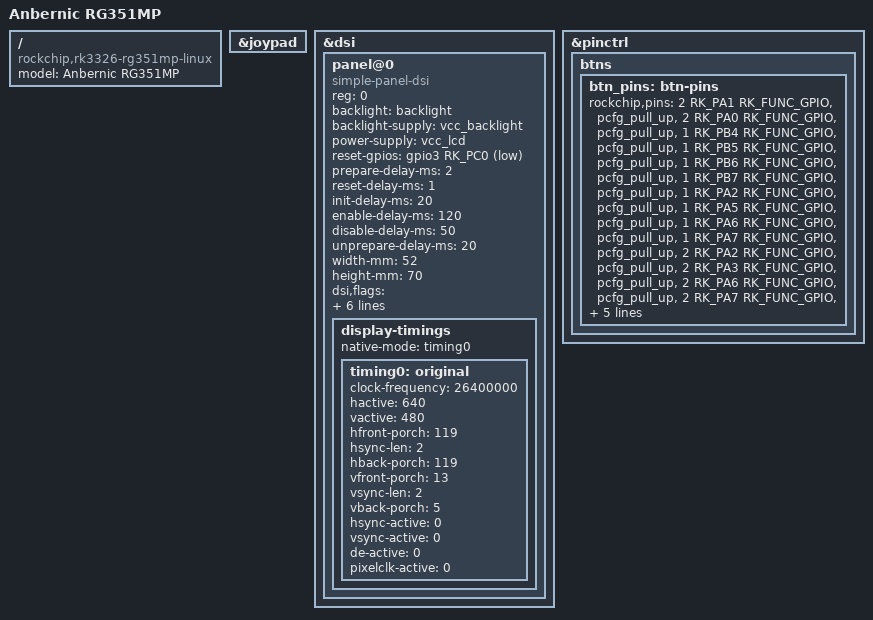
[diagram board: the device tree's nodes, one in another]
// SPDX-License-Identifier: (GPL-2.0+ OR MIT)
/*
* Copyright (c) 2026 kk&lcdyk
*
* Anbernic RG351MP
*
*/

/dts-v1/;
#include "rk3326-r36s-panel0-linux.dts"

/ {
	model = "Anbernic RG351MP";
	compatible = "rockchip,rk3326-rg351mp-linux", "rockchip,rk3326";
};

&joypad {
    /delete-node/ sw13;
};

&dsi {
	status = "okay";
	
	panel@0 {
		compatible = "simple-panel-dsi";
		reg = <0>;
		/* pwm1 backlight */
		backlight = <&backlight>;
		/* RK817 LDO7 */
		backlight-supply = <&vcc_backlight>;
		/* RK817 LDO8 */
		power-supply = <&vcc_lcd>;
		/* Rev 0.2 LCD reset gpio GPIO3.C0 */
		reset-gpios = <&gpio3 RK_PC0 GPIO_ACTIVE_LOW>;
		prepare-delay-ms = <2>;
		reset-delay-ms = <1>;
		init-delay-ms = <20>;
		enable-delay-ms = <120>;
		disable-delay-ms = <50>;
		unprepare-delay-ms = <20>;
		width-mm = <52>;
		height-mm = <70>;
		dsi,flags  = <(MIPI_DSI_MODE_VIDEO |
		MIPI_DSI_MODE_VIDEO_BURST |
		MIPI_DSI_MODE_LPM |
		MIPI_DSI_MODE_EOT_PACKET)>;
		dsi,format = <MIPI_DSI_FMT_RGB888>;
		dsi,lanes = <4>;
		panel-init-sequence = [ 15 00 02 FF 30 15 00 02 FF 52 15 00 02 FF 01 15 00 02 E3 00 15 00 02 40 0A 15 00 02 03 40 15 00 02 04 00 15 00 02 05 03 15 00 02 24 12 15 00 02 25 1E 15 00 02 26 28 15 00 02 27 52 15 00 02 28 57 15 00 02 29 01 15 00 02 2A DF 15 00 02 38 9C 15 00 02 39 A7 15 00 02 3A 53 15 00 02 44 00 15 00 02 49 3C 15 00 02 59 FE 15 00 02 5C 00 15 00 02 91 77 15 00 02 92 77 15 00 02 A0 55 15 00 02 A1 50 15 00 02 A4 9C 15 00 02 A7 02 15 00 02 A8 01 15 00 02 A9 01 15 00 02 AA FC 15 00 02 AB 28 15 00 02 AC 06 15 00 02 AD 06 15 00 02 AE 06 15 00 02 AF 03 15 00 02 B0 08 15 00 02 B1 26 15 00 02 B2 28 15 00 02 B3 28 15 00 02 B4 33 15 00 02 B5 08 15 00 02 B6 26 15 00 02 B7 08 15 00 02 B8 26 15 00 02 FF 30 15 00 02 FF 52 15 00 02 FF 02 15 00 02 B0 0B 15 00 02 B1 16 15 00 02 B2 17 15 00 02 B3 2C 15 00 02 B4 32 15 00 02 B5 3B 15 00 02 B6 29 15 00 02 B7 40 15 00 02 B8 0D 15 00 02 B9 05 15 00 02 BA 12 15 00 02 BB 10 15 00 02 BC 12 15 00 02 BD 15 15 00 02 BE 19 15 00 02 BF 0E 15 00 02 C0 16 15 00 02 C1 0A 15 00 02 D0 0C 15 00 02 D1 17 15 00 02 D2 14 15 00 02 D3 2E 15 00 02 D4 32 15 00 02 D5 3C 15 00 02 D6 22 15 00 02 D7 3D 15 00 02 D8 0D 15 00 02 D9 07 15 00 02 DA 13 15 00 02 DB 13 15 00 02 DC 11 15 00 02 DD 15 15 00 02 DE 19 15 00 02 DF 10 15 00 02 E0 17 15 00 02 E1 0A 15 00 02 FF 30 15 00 02 FF 52 15 00 02 FF 03 15 00 02 00 2A 15 00 02 01 2A 15 00 02 02 2A 15 00 02 03 2A 15 00 02 04 61 15 00 02 05 80 15 00 02 06 C7 15 00 02 07 01 15 00 02 08 82 15 00 02 09 83 15 00 02 30 2A 15 00 02 31 2A 15 00 02 32 2A 15 00 02 33 2A 15 00 02 34 61 15 00 02 35 C5 15 00 02 36 80 15 00 02 37 23 15 00 02 40 82 15 00 02 41 83 15 00 02 42 80 15 00 02 43 81 15 00 02 44 11 15 00 02 45 E6 15 00 02 46 E5 15 00 02 47 11 15 00 02 48 E8 15 00 02 49 E7 15 00 02 50 02 15 00 02 51 01 15 00 02 52 04 15 00 02 53 03 15 00 02 54 11 15 00 02 55 EA 15 00 02 56 E9 15 00 02 57 11 15 00 02 58 EC 15 00 02 59 EB 15 00 02 7E 02 15 00 02 7F 80 15 00 02 E0 5A 15 00 02 B1 00 15 00 02 B4 0E 15 00 02 B5 0F 15 00 02 B6 04 15 00 02 B7 07 15 00 02 B8 06 15 00 02 B9 05 15 00 02 BA 0F 15 00 02 C7 00 15 00 02 CA 0E 15 00 02 CB 0F 15 00 02 CC 04 15 00 02 CD 07 15 00 02 CE 06 15 00 02 CF 05 15 00 02 D0 0F 15 00 02 81 0F 15 00 02 84 0E 15 00 02 85 0F 15 00 02 86 07 15 00 02 87 04 15 00 02 88 05 15 00 02 89 06 15 00 02 8A 00 15 00 02 97 0F 15 00 02 9A 0E 15 00 02 9B 0F 15 00 02 9C 07 15 00 02 9D 04 15 00 02 9E 05 15 00 02 9F 06 15 00 02 A0 00 15 00 02 FF 30 15 00 02 FF 52 15 00 02 FF 02 15 00 02 01 01 15 00 02 02 DA 15 00 02 03 BA 15 00 02 04 A8 15 00 02 05 9A 15 00 02 06 70 15 00 02 07 FF 15 00 02 08 91 15 00 02 09 90 15 00 02 0A FF 15 00 02 0B 8F 15 00 02 0C 60 15 00 02 0D 58 15 00 02 0E 48 15 00 02 0F 38 15 00 02 10 2B 15 00 02 FF 30 15 00 02 FF 52 15 00 02 FF 00 15 00 02 36 02 15 00 02 3A 70 05 C8 01 11 05 0A 01 29];
		panel-exit-sequence = [05 14 01 28 05 0A 01 10];
		
		display-timings {
			native-mode = <&timing0>;
			
			// 26.40MHz / (640+119+2+119)×(480+13+2+5) = 880×500 = 60.00 Hz
			timing0: original {
				clock-frequency = <26400000>;
				hactive = <640>;
				vactive = <480>;
				hfront-porch = <119>;
				hsync-len = <2>;
				hback-porch = <119>;
				vfront-porch = <13>;
				vsync-len = <2>;
				vback-porch = <5>;
				hsync-active = <0>;
				vsync-active = <0>;
				de-active = <0>;
				pixelclk-active = <0>;
			};
		};
	};
};

&pinctrl {
	btns {
		btn_pins: btn-pins {
			rockchip,pins =
			<2 RK_PA1 RK_FUNC_GPIO &pcfg_pull_up>,
			<2 RK_PA0 RK_FUNC_GPIO &pcfg_pull_up>,
			<1 RK_PB4 RK_FUNC_GPIO &pcfg_pull_up>,
			<1 RK_PB5 RK_FUNC_GPIO &pcfg_pull_up>,
			<1 RK_PB6 RK_FUNC_GPIO &pcfg_pull_up>,
			<1 RK_PB7 RK_FUNC_GPIO &pcfg_pull_up>,
			<1 RK_PA2 RK_FUNC_GPIO &pcfg_pull_up>,
			<1 RK_PA5 RK_FUNC_GPIO &pcfg_pull_up>,
			<1 RK_PA6 RK_FUNC_GPIO &pcfg_pull_up>,
			<1 RK_PA7 RK_FUNC_GPIO &pcfg_pull_up>,
			<2 RK_PA2 RK_FUNC_GPIO &pcfg_pull_up>,
			<2 RK_PA3 RK_FUNC_GPIO &pcfg_pull_up>,
			<2 RK_PA6 RK_FUNC_GPIO &pcfg_pull_up>,
			<2 RK_PA7 RK_FUNC_GPIO &pcfg_pull_up>,
			<3 RK_PB1 RK_FUNC_GPIO &pcfg_pull_up>,
			<3 RK_PB7 RK_FUNC_GPIO &pcfg_pull_up>,
			<3 RK_PB2 RK_FUNC_GPIO &pcfg_pull_up>,
			<3 RK_PB4 RK_FUNC_GPIO &pcfg_pull_up>;
		};
	};
};

/* DON'T PUT ANYTHING BELOW HERE.  PUT IT ABOVE PINCTRL */

